VERSION ""

NS_ :

BS_:

BU_: ecm ipc bcm srs tcm

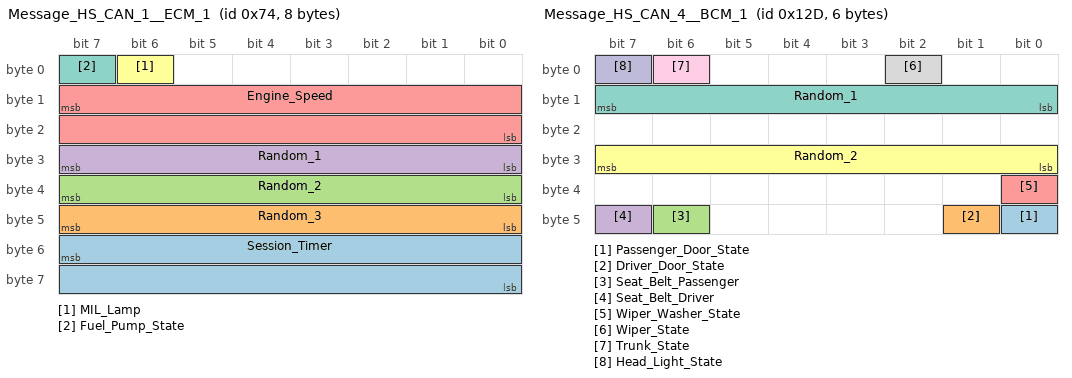
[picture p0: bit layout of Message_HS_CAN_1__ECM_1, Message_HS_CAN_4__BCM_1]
BO_ 116 Message_HS_CAN_1__ECM_1: 8 ecm
 SG_ Session_Timer : 55|16@0+ (1,0) [0|65535] "" Vector__XXX
 SG_ Random_3 : 47|8@0+ (1,0) [0|255] "" Vector__XXX
 SG_ Random_2 : 39|8@0+ (1,0) [0|255] "" Vector__XXX
 SG_ Random_1 : 31|8@0+ (1,0) [0|255] "" Vector__XXX
 SG_ Engine_Speed : 15|16@0+ (0.25,0) [0|16383.75] "RPM" Vector__XXX
 SG_ MIL_Lamp : 6|1@0+ (1,0) [0|0] "" Vector__XXX
 SG_ Fuel_Pump_State : 7|1@0+ (1,0) [0|0] "" Vector__XXX

BO_ 1068 Message_HS_CAN_2__ECM_: 8 ecm
 SG_ Nonce : 16|32@1+ (1,0) [0|4294967295] "" Vector__XXX
 SG_ Seed : 7|16@0+ (1,0) [0|65535] "" Vector__XXX

BO_ 301 Message_HS_CAN_4__BCM_1: 6 bcm
 SG_ Passenger_Door_State : 40|1@0+ (1,0) [0|0] "" Vector__XXX
 SG_ Driver_Door_State : 41|1@0+ (1,0) [0|0] "" Vector__XXX
 SG_ Seat_Belt_Passenger : 46|1@0+ (1,0) [0|0] "" Vector__XXX
 SG_ Seat_Belt_Driver : 47|1@0+ (1,0) [0|0] "" Vector__XXX
 SG_ Wiper_Washer_State : 32|1@0+ (1,0) [0|0] "" Vector__XXX
 SG_ Random_2 : 31|8@0+ (1,0) [0|255] "" Vector__XXX
 SG_ Random_1 : 15|8@0+ (1,0) [0|255] "" Vector__XXX
 SG_ Wiper_State : 2|1@0+ (1,0) [0|0] "" Vector__XXX
 SG_ Trunk_State : 6|1@0+ (1,0) [0|0] "" Vector__XXX
 SG_ Head_Light_State : 7|1@0+ (1,0) [0|0] "" Vector__XXX

BO_ 750 Message_HS_CAN_5__BCM_: 6 bcm
 SG_ Seed : 39|16@0+ (1,0) [0|65535] "" Vector__XXX
 SG_ Nonce : 0|32@1+ (1,0) [0|4294967295] "" Vector__XXX

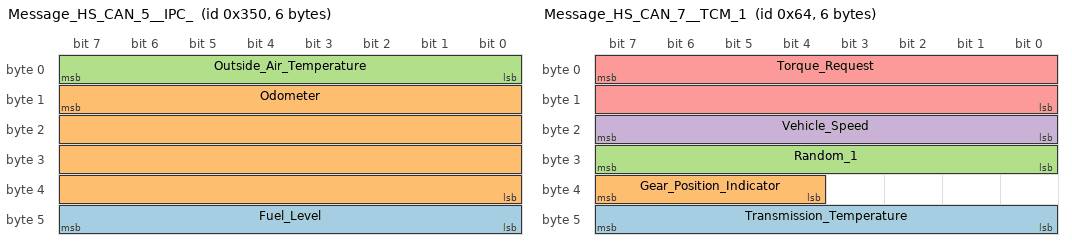
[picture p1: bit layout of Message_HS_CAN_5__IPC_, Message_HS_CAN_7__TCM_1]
BO_ 848 Message_HS_CAN_5__IPC_: 6 ipc
 SG_ Fuel_Level : 47|8@0+ (0.5,0) [0|127.5] "" Vector__XXX
 SG_ Odometer : 15|32@0+ (0.01,0) [0|42949672.95] "" Vector__XXX
 SG_ Outside_Air_Temperature : 7|8@0+ (1,-40) [-40|215] "" Vector__XXX

BO_ 1056 Message_HS_CAN_6__IPC_: 6 ipc
 SG_ Seed : 39|16@0+ (1,0) [0|65535] "" Vector__XXX
 SG_ Nonce : 7|32@0+ (1,0) [0|4294967295] "" Vector__XXX

BO_ 100 Message_HS_CAN_7__TCM_1: 6 tcm
 SG_ Transmission_Temperature : 47|8@0+ (1,0) [0|255] "" Vector__XXX
 SG_ Gear_Position_Indicator : 39|4@0+ (1,0) [0|15] "" Vector__XXX
 SG_ Random_1 : 31|8@0+ (1,0) [0|255] "" Vector__XXX
 SG_ Vehicle_Speed : 23|8@0+ (0.5,0) [0|127.5] "" Vector__XXX
 SG_ Torque_Request : 7|16@0+ (0.01,-100) [-100|555.35] "" Vector__XXX

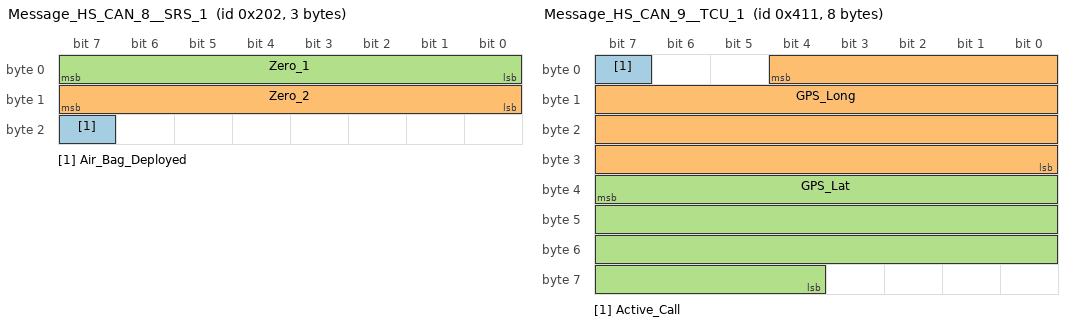
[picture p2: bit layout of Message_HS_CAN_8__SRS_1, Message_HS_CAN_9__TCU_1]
BO_ 514 Message_HS_CAN_8__SRS_1: 3 srs
 SG_ Air_Bag_Deployed : 23|1@0+ (1,0) [0|0] "" Vector__XXX
 SG_ Zero_2 : 15|8@0+ (1,0) [0|255] "" Vector__XXX
 SG_ Zero_1 : 7|8@0+ (1,0) [0|255] "" Vector__XXX

BO_ 1041 Message_HS_CAN_9__TCU_1: 8 tcu
 SG_ Active_Call : 7|1@0+ (1,0) [0|0] "" Vector__XXX
 SG_ GPS_Long : 4|29@0- (1e-06,0) [-268.435456|268.435455] "" Vector__XXX
 SG_ GPS_Lat : 39|28@0- (1e-06,0) [-134.217728|134.217727] "" Vector__XXX

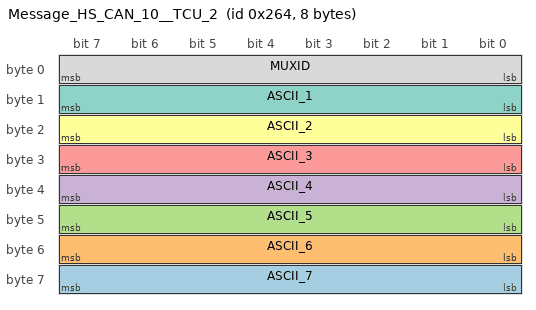
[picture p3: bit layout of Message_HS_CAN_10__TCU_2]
BO_ 612 Message_HS_CAN_10__TCU_2: 8 tcu
 SG_ ASCII_7 : 63|8@0+ (1,0) [0|255] "" Vector__XXX
 SG_ ASCII_6 : 55|8@0+ (1,0) [0|255] "" Vector__XXX
 SG_ ASCII_5 : 47|8@0+ (1,0) [0|255] "" Vector__XXX
 SG_ ASCII_4 : 39|8@0+ (1,0) [0|255] "" Vector__XXX
 SG_ ASCII_3 : 31|8@0+ (1,0) [0|255] "" Vector__XXX
 SG_ ASCII_2 : 23|8@0+ (1,0) [0|255] "" Vector__XXX
 SG_ ASCII_1 : 15|8@0+ (1,0) [0|255] "" Vector__XXX
 SG_ MUXID : 7|8@0+ (1,0) [0|255] "" Vector__XXX

BA_DEF_ BO_  "GenMsgCycleTime" INT 0 10000;
BA_DEF_DEF_  "GenMsgCycleTime" 0;
BA_ "GenMsgCycleTime" BO_ 116 10;
BA_ "GenMsgCycleTime" BO_ 1068 50;
BA_ "GenMsgCycleTime" BO_ 301 25;
BA_ "GenMsgCycleTime" BO_ 750 50;
BA_ "GenMsgCycleTime" BO_ 848 20;
BA_ "GenMsgCycleTime" BO_ 1056 60;
BA_ "GenMsgCycleTime" BO_ 100 100;
BA_ "GenMsgCycleTime" BO_ 514 10;
